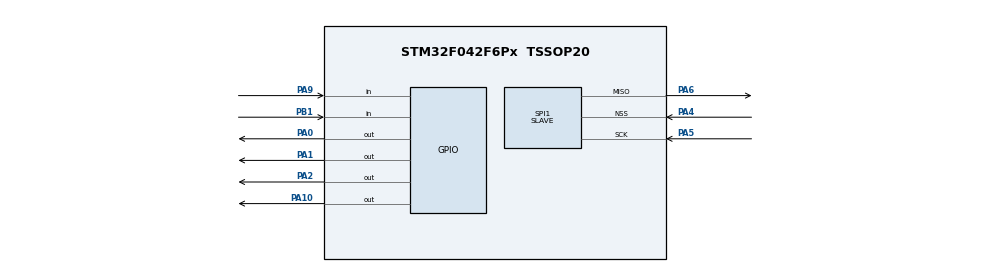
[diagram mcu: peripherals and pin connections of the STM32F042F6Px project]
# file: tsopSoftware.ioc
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Mcu.Family=STM32F0
Mcu.Name=STM32F042F6Px
Mcu.Package=TSSOP20
PA0.GPIO_Speed=GPIO_SPEED_FREQ_HIGH
PA0.Signal=GPIO_Output
PA1.GPIO_Speed=GPIO_SPEED_FREQ_HIGH
PA1.Signal=GPIO_Output
PA10.GPIO_Speed=GPIO_SPEED_FREQ_HIGH
PA10.Signal=GPIO_Output
PA2.GPIO_Speed=GPIO_SPEED_FREQ_HIGH
PA2.Signal=GPIO_Output
PA4.GPIO_PuPd=GPIO_NOPULL
PA4.GPIO_Speed=GPIO_SPEED_FREQ_MEDIUM
PA4.Mode=NSS_Signal_Hard_Input
PA4.Signal=SPI1_NSS
PA5.GPIO_Speed=GPIO_SPEED_FREQ_MEDIUM
PA5.Mode=TX_Only_Simplex_Unidirect_Slave
PA5.Signal=SPI1_SCK
PA6.GPIO_Speed=GPIO_SPEED_FREQ_MEDIUM
PA6.Mode=TX_Only_Simplex_Unidirect_Slave
PA6.Signal=SPI1_MISO
PA7.Signal=SPI1_MOSI
PA9.Signal=GPIO_Input
PB1.Signal=GPIO_Input
PF0-OSC_IN.Mode=HSE-External-Oscillator
PF0-OSC_IN.Signal=RCC_OSC_IN
PF1-OSC_OUT.Mode=HSE-External-Oscillator
PF1-OSC_OUT.Signal=RCC_OSC_OUT
ProjectManager.HeapSize=0x200
ProjectManager.StackSize=0x400
ProjectManager.TargetToolchain=STM32CubeIDE
RCC.HSE_VALUE=12000000
SPI1.Direction=SPI_DIRECTION_2LINES
SPI1.Mode=SPI_MODE_SLAVE
SPI1.VirtualNSS=VM_NSSHARD
SPI1.VirtualType=VM_SLAVE
board=custom

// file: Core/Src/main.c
/* USER CODE BEGIN Header */
/**
  ******************************************************************************
  * @file           : main.c
  * @brief          : Main program body
  ******************************************************************************
  * @attention
  *
  * <h2><center>&copy; Copyright (c) 2021 STMicroelectronics.
  * All rights reserved.</center></h2>
  *
  * This software component is licensed by ST under BSD 3-Clause license,
  * the "License"; You may not use this file except in compliance with the
  * License. You may obtain a copy of the License at:
  *                        opensource.org/licenses/BSD-3-Clause
  *
  ******************************************************************************
  */
/* USER CODE END Header */
#include "main.h"

SPI_HandleTypeDef hspi1;

void SystemClock_Config(void);
static void MX_GPIO_Init(void);
static void MX_SPI1_Init(void);

//static _Bool muxChannel[16][4] = {
//  {0, 0, 0, 0}, //channel 0
//  {1, 0, 0, 0}, //channel 1
//  {0, 1, 0, 0}, //channel 2
//  {1, 1, 0, 0}, //channel 3
//  {0, 0, 1, 0}, //channel 4
//  {1, 0, 1, 0}, //channel 5
//  {0, 1, 1, 0}, //channel 6
//  {1, 1, 1, 0}, //channel 7
//  {0, 0, 0, 1}, //channel 8
//  {1, 0, 0, 1}, //channel 9
//  {0, 1, 0, 1}, //channel 10
//  {1, 1, 0, 1}, //channel 11
//  {0, 0, 1, 1}, //channel 12
//  {1, 0, 1, 1}, //channel 13
//  {0, 1, 1, 1}, //channel 14
//  {1, 1, 1, 1} //channel 15
//};
//
//void turnLow() {
//	HAL_GPIO_WritePin(GPIOA, GPIO_PIN_1 | GPIO_PIN_0 | GPIO_PIN_10 | GPIO_PIN_2, GPIO_PIN_RESET);
//}
//
//uint8_t readMux(int mux, int channel) {
//  turnLow();
//  if(muxChannel[channel][0])
//	  HAL_GPIO_WritePin(GPIOA, GPIO_PIN_1, GPIO_PIN_SET);
//  else
//	  HAL_GPIO_WritePin(GPIOA, GPIO_PIN_1, GPIO_PIN_RESET);
//  if(muxChannel[channel][1])
//  	  HAL_GPIO_WritePin(GPIOA, GPIO_PIN_0, GPIO_PIN_SET);
//  else
//  	  HAL_GPIO_WritePin(GPIOA, GPIO_PIN_0, GPIO_PIN_RESET);
//  if(muxChannel[channel][2])
//  	  HAL_GPIO_WritePin(GPIOA, GPIO_PIN_10, GPIO_PIN_SET);
//  else
//  	  HAL_GPIO_WritePin(GPIOA, GPIO_PIN_10, GPIO_PIN_RESET);
//  if(muxChannel[channel][3])
//  	  HAL_GPIO_WritePin(GPIOA, GPIO_PIN_2, GPIO_PIN_SET);
//  else
//  	  HAL_GPIO_WritePin(GPIOA, GPIO_PIN_2, GPIO_PIN_RESET);
//
//  //return the value
//  if (mux == 1)
//  {
//	  if(HAL_GPIO_ReadPin(GPIOB, GPIO_PIN_1) == GPIO_PIN_SET) {
//	      return 1;
//	  }
//	  else {
//	      return 0;
//	  }
//  }
//  if(HAL_GPIO_ReadPin(GPIOA, GPIO_PIN_9) == GPIO_PIN_SET) {
//      return 1;
//  }
//  else {
//      return 0;
//  }
//}
//
//double toRadians(double degs) {
//  return degs * 3.1415926553 / 180;
//}
//
//float getAngle(float x, float y) {
//  float angle = atan2(x, y) * 57.2928;
//  if (angle < 0)
//    angle = 360 + angle;
//  return angle;
//}
//
//float getX(int tsop_results[]) {
//  float x = 0;
//  for (int i = 0; i < 32; ++i)
//    x += sin(toRadians(11.25 * i)) * tsop_results[i];
//  return x;
//}
//
//float getY(int tsop_results[]) {
//  float y = 0;
//  for (int i = 0; i < 32; ++i)
//    y += cos(toRadians(11.25 * i)) * tsop_results[i];
//  return y;
//}
//
//float getDist(float x, float y) {
//	if(x * x + y * y > 0)
//		return sqrt(x * x + y * y);
//	return sqrt(-(x * x + y * y));
//}

int main(void)
{
  /* USER CODE BEGIN 1 */

	//int data[32];

	//uint8_t dataToSend[2];

	uint8_t dts;

	//uint8_t ang = 0, distance = 0;

  /* USER CODE END 1 */

  /* MCU Configuration--------------------------------------------------------*/

  /* Reset of all peripherals, Initializes the Flash interface and the Systick. */
  HAL_Init();

  /* Configure the system clock */
  SystemClock_Config();

  MX_GPIO_Init();
  MX_SPI1_Init();
  /* Initialize all configured peripherals */
  /* Infinite loop */
  /* USER CODE BEGIN WHILE */
  while (1)
  {
//	for(int mux = 1; mux < 3; ++mux)
//		for(int i = 0; i < 16; ++i)
//			data[i + (mux-1)*16] = readMux(mux, i);
//
//	ang = (uint8_t)getAngle(getX(data), getY(data));
//	distance = (uint8_t)getDist(getX(data), getY(data));
//
//	dataToSend[0] = ang;
//    dataToSend[1] = distance;
    dts = 3;

	HAL_SPI_Transmit(&hspi1, dts, 1, 300);
  }
  /* USER CODE END 3 */
}

void SystemClock_Config(void)
{
  RCC_OscInitTypeDef RCC_OscInitStruct = {0};
  RCC_ClkInitTypeDef RCC_ClkInitStruct = {0};

  /** Initializes the RCC Oscillators according to the specified parameters
  * in the RCC_OscInitTypeDef structure.
  */
  RCC_OscInitStruct.OscillatorType = RCC_OSCILLATORTYPE_HSI;
  RCC_OscInitStruct.HSIState = RCC_HSI_ON;
  RCC_OscInitStruct.HSICalibrationValue = RCC_HSICALIBRATION_DEFAULT;
  RCC_OscInitStruct.PLL.PLLState = RCC_PLL_NONE;
  if (HAL_RCC_OscConfig(&RCC_OscInitStruct) != HAL_OK)
  {
    Error_Handler();
  }
  /** Initializes the CPU, AHB and APB buses clocks
  */
  RCC_ClkInitStruct.ClockType = RCC_CLOCKTYPE_HCLK|RCC_CLOCKTYPE_SYSCLK
                              |RCC_CLOCKTYPE_PCLK1;
  RCC_ClkInitStruct.SYSCLKSource = RCC_SYSCLKSOURCE_HSI;
  RCC_ClkInitStruct.AHBCLKDivider = RCC_SYSCLK_DIV1;
  RCC_ClkInitStruct.APB1CLKDivider = RCC_HCLK_DIV1;

  if (HAL_RCC_ClockConfig(&RCC_ClkInitStruct, FLASH_LATENCY_0) != HAL_OK)
  {
    Error_Handler();
  }
}

static void MX_SPI1_Init(void)
{

  /* SPI1 parameter configuration*/
  hspi1.Instance = SPI1;
  hspi1.Init.Mode = SPI_MODE_SLAVE;
  hspi1.Init.Direction = SPI_DIRECTION_2LINES;
  hspi1.Init.DataSize = SPI_DATASIZE_4BIT;
  hspi1.Init.CLKPolarity = SPI_POLARITY_LOW;
  hspi1.Init.CLKPhase = SPI_PHASE_1EDGE;
  hspi1.Init.NSS = SPI_NSS_HARD_INPUT;
  hspi1.Init.FirstBit = SPI_FIRSTBIT_MSB;
  hspi1.Init.TIMode = SPI_TIMODE_DISABLE;
  hspi1.Init.CRCCalculation = SPI_CRCCALCULATION_DISABLE;
  hspi1.Init.CRCPolynomial = 7;
  hspi1.Init.CRCLength = SPI_CRC_LENGTH_DATASIZE;
  hspi1.Init.NSSPMode = SPI_NSS_PULSE_DISABLE;
  if (HAL_SPI_Init(&hspi1) != HAL_OK)
  {
    Error_Handler();
  }

}

static void MX_GPIO_Init(void)
{
  GPIO_InitTypeDef GPIO_InitStruct = {0};

  /* GPIO Ports Clock Enable */
  __HAL_RCC_GPIOF_CLK_ENABLE();
  __HAL_RCC_GPIOA_CLK_ENABLE();
  __HAL_RCC_GPIOB_CLK_ENABLE();

  /*Configure GPIO pin Output Level */
  HAL_GPIO_WritePin(GPIOA, GPIO_PIN_0|GPIO_PIN_1|GPIO_PIN_2|GPIO_PIN_10, GPIO_PIN_RESET);

  /*Configure GPIO pins : PA0 PA1 PA2 PA10 */
  GPIO_InitStruct.Pin = GPIO_PIN_0|GPIO_PIN_1|GPIO_PIN_2|GPIO_PIN_10;
  GPIO_InitStruct.Mode = GPIO_MODE_OUTPUT_PP;
  GPIO_InitStruct.Pull = GPIO_NOPULL;
  GPIO_InitStruct.Speed = GPIO_SPEED_FREQ_HIGH;
  HAL_GPIO_Init(GPIOA, &GPIO_InitStruct);

  /*Configure GPIO pin : PB1 */
  GPIO_InitStruct.Pin = GPIO_PIN_1;
  GPIO_InitStruct.Mode = GPIO_MODE_INPUT;
  GPIO_InitStruct.Pull = GPIO_NOPULL;
  HAL_GPIO_Init(GPIOB, &GPIO_InitStruct);

  /*Configure GPIO pin : PA9 */
  GPIO_InitStruct.Pin = GPIO_PIN_9;
  GPIO_InitStruct.Mode = GPIO_MODE_INPUT;
  GPIO_InitStruct.Pull = GPIO_NOPULL;
  HAL_GPIO_Init(GPIOA, &GPIO_InitStruct);

}

void Error_Handler(void)
{
  __disable_irq();
  while (1)
  {
  }
}

/************************ (C) COPYRIGHT STMicroelectronics *****END OF FILE****/
